# GD32H71x_72x register map
File version: 1.0
CPU: CM7 r1p2, little endian, MPU, FPU, 4 interrupt priority bits
Registers are 32-bit, read-write, reset 0x0 unless marked. A register's access mark holds for its fields unless they carry their own. Offsets are from the block's base; [hi:lo] are bit positions; {n}, {i} and the like mark numbered series.

## HDSL0_SAFE_CHANNEL_2 — HDSL0 Safe Channel 2 Interface Registers
Base 0x4000DB00
Same registers: HDSL1_SAFE_CHANNEL_2 0x40002F00
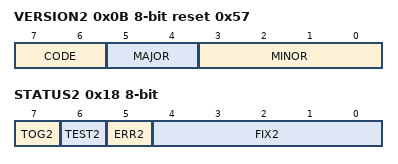
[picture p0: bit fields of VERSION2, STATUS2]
0x0B VERSION2 8-bit ro reset 0x57 — HDSL version in safe channel 2 register
  [7:6] CODE — Type of module01: HDSL MasterOthers: Reserved
  [5:4] MAJOR — Major release numberThe current version is 1.
  [3:0] MINOR — Minor release numberThe current version is 7.
0x0F ENC2_ID 8-bit ro — HDSL encoder ID in safe channel 2 register
  [7:0] ENC2ID — Designation of the safe channel 2 channel
0x18 STATUS2 8-bit ro — HDSL safe channel 2 status register
  [7] TOG2 — Safe Channel 2 Toggle
  [6] TEST2 — Safe Channel 2 Test
  [5] ERR2 — Safe Channel 2 Position Error
  [4:0] FIX2 — Safe Channel 2 Fixed Bit Pattern
0x19 VPOS2_4 8-bit ro — HDSL safe position channel 2 byte 4 register
  [7:0] VPOS2 — Safe position, Channel 2, byte 4
0x1A VPOS2_3 8-bit ro — HDSL safe position channel 2 byte 3 register
  [7:0] VPOS2 — Safe position, Channel 2, byte 3
0x1B VPOS2_2 8-bit ro — HDSL safe position channel 2 byte 2 register
  [7:0] VPOS2 — Safe position, Channel 2, byte 2
0x1C VPOS2_1 8-bit ro — HDSL safe position channel 2 byte 1 register
  [7:0] VPOS2 — Safe position, Channel 2, byte 1
0x1D VPOS2_0 8-bit ro — HDSL safe position channel 2 byte 0 register
  [7:0] VPOS2 — Safe position, Channel 2, byte 0
0x1E VPOSCRC2_H 8-bit ro — HDSL high byte position checksum channel 2 register
  [7:0] VPOSCRC2H — CRC of the safe position 2, bit 15 to bit 8
0x1F VPOSCRC2_L 8-bit ro — HDSL low byte position checksum channel 2 register
  [7:0] VPOSCRC2L — CRC of the safe position 2, bit 7 to bit 0
0x3F DUMMY2 8-bit ro — HDSL dummy in safe channel 2 register
  [7:0] DUMMY — Dummy field for safe channel 2

## HWSEM — Hardware semaphore
Base 0x58026400
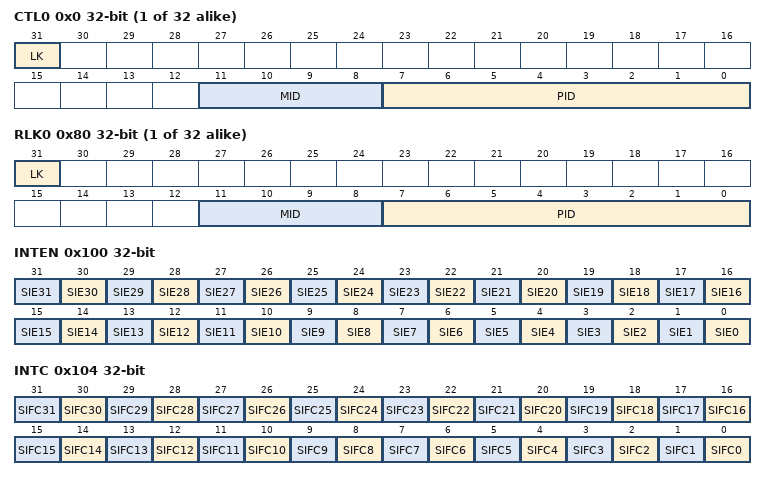
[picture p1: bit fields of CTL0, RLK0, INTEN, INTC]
{0x0+4i} CTL{i} (i=0..31) — Control regist {i}
  [31] LK — Lock semaphore
  [11:8] MID — AHB bus master identification
  [7:0] PID — Process identification
{0x80+4i} RLK{i} ro (i=0..31) — Read lock regist {i}
  [31] LK — Lock semaphore by reading
  [11:8] MID — Bus master identification
  [7:0] PID — Process identification
0x100 INTEN — Interrupt enable register
  [n] SIE{n} (n=0..31) — Semaphore interrupt enable bit
0x104 INTC wo — Interrupt flag clear register
  [n] SIFC{n} (n=0..31) — Semaphore interrupt flag clear bit
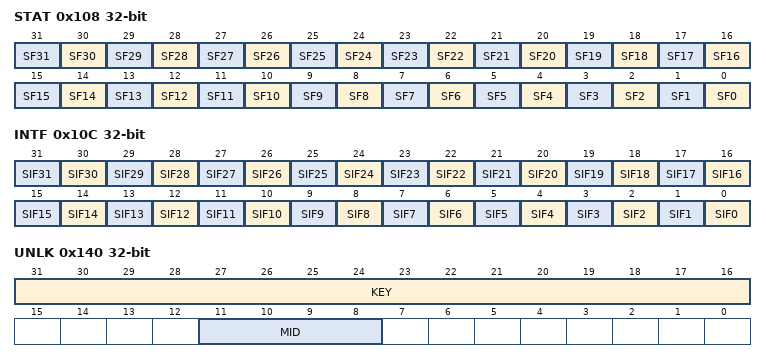
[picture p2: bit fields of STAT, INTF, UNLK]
0x108 STAT ro — Status register
  [n] SF{n} (n=0..31) — Semaphore flag
0x10C INTF ro — Interrupt flag register
  [n] SIF{n} (n=0..31) — Semaphore interrupt flag status
0x140 UNLK wo — Unlock register
  [31:16] KEY — Key value
  [11:8] MID — Bus master identification to clear
0x144 KEY
  [31:16] KEY — Key for unlocking all semaphores of a bus master

## LPDTS — Low power digital temperature sensor
Base 0x58006800
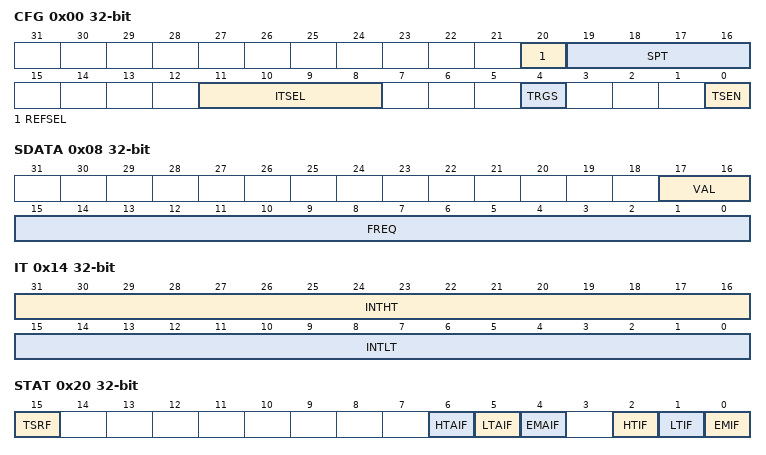
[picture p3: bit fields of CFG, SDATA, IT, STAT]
0x00 CFG — Configuration register
  [20] REFSEL — Reference clock selection
  [19:16] SPT — Sampling time
  [11:8] ITSEL — Input trigger selection
  [4] TRGS — Trigger selection for frequency measurement
  [0] TSEN — Enable temperature sensor
0x08 SDATA ro — Sensor T0 data register
  [17:16] VAL — The collected temperature value
  [15:0] FREQ — Frequency value
0x10 RDATA ro — Ramp data register
  [15:0] RCVAL — Ramp coefficient
0x14 IT — Interrupt threshold register
  [31:16] INTHT — Interrupt high threshold
  [15:0] INTLT — Interrupt low threshold
0x1C DATA ro — Temperature data register
  [15:0] COVAL — Value of the counter output
0x20 STAT ro — Temperature sensor status register
  [15] TSRF — Temperature sensor ready flag
  [6] HTAIF — High threshold asynchronous interrupt flag
  [5] LTAIF — Low threshold asynchronous interrupt flag
  [4] EMAIF — End of measurement asynchronous interrupt flag
  [2] HTIF — High threshold interrupt flag
  [1] LTIF — Low threshold interrupt flag
  [0] EMIF — End of measurement interrupt flag
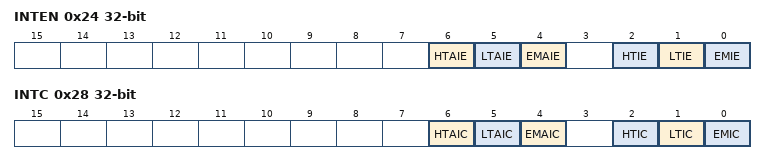
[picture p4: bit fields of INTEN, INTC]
0x24 INTEN — Interrupt enable register
  [6] HTAIE — High threshold asynchronous interrupt enable
  [5] LTAIE — Low threshold asynchronous interrupt enable
  [4] EMAIE — End of measurement asynchronous interrupt enable
  [2] HTIE — High threshold interrupt enable
  [1] LTIE — Low threshold interrupt enable
  [0] EMIE — End of measurement interrupt enable
0x28 INTC — Interrupt clear flag register
  [6] HTAIC — High threshold asynchronous interrupt clear
  [5] LTAIC — Low threshold asynchronous interrupt clear
  [4] EMAIC — End of Measure asynchronous interrupt clear
  [2] HTIC — High threshold interrupt clear
  [1] LTIC — Low threshold interrupt clear
  [0] EMIC — End of measurement interrupt clear
0x2C OP — Option register
  [31:0] OP — general purpose option bits
